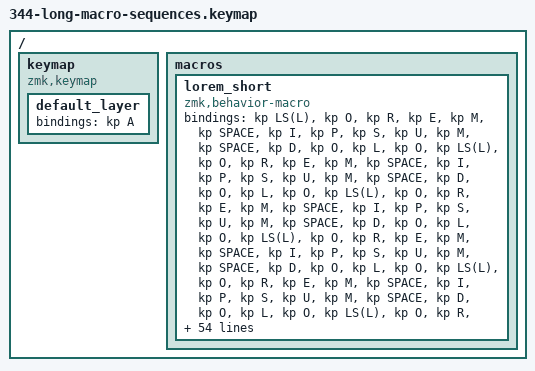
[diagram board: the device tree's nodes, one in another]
/* Issue #344: long macro payload regression; representative source from the issue comments. */
/{
    keymap {
        compatible = "zmk,keymap";
        default_layer { bindings = <&kp A>; };
    };
    macros {
        lorem_short: lorem_short {
            compatible = "zmk,behavior-macro";
            #binding-cells = <0>;
            bindings = <&kp LS(L) &kp O &kp R &kp E &kp M &kp SPACE &kp I &kp P &kp S &kp U &kp M &kp SPACE &kp D &kp O &kp L &kp O &kp LS(L) &kp O &kp R &kp E &kp M &kp SPACE &kp I &kp P &kp S &kp U &kp M &kp SPACE &kp D &kp O &kp L &kp O &kp LS(L) &kp O &kp R &kp E &kp M &kp SPACE &kp I &kp P &kp S &kp U &kp M &kp SPACE &kp D &kp O &kp L &kp O &kp LS(L) &kp O &kp R &kp E &kp M &kp SPACE &kp I &kp P &kp S &kp U &kp M &kp SPACE &kp D &kp O &kp L &kp O &kp LS(L) &kp O &kp R &kp E &kp M &kp SPACE &kp I &kp P &kp S &kp U &kp M &kp SPACE &kp D &kp O &kp L &kp O &kp LS(L) &kp O &kp R &kp E &kp M &kp SPACE &kp I &kp P &kp S &kp U &kp M &kp SPACE &kp D &kp O &kp L &kp O &kp LS(L) &kp O &kp R &kp E &kp M &kp SPACE &kp I &kp P &kp S &kp U &kp M &kp SPACE &kp D &kp O &kp L &kp O &kp LS(L) &kp O &kp R &kp E &kp M &kp SPACE &kp I &kp P &kp S &kp U &kp M &kp SPACE &kp D &kp O &kp L &kp O &kp LS(L) &kp O &kp R &kp E &kp M &kp SPACE &kp I &kp P &kp S &kp U &kp M &kp SPACE &kp D &kp O &kp L &kp O &kp LS(L) &kp O &kp R &kp E &kp M &kp SPACE &kp I &kp P &kp S &kp U &kp M &kp SPACE &kp D &kp O &kp L &kp O &kp LS(L) &kp O &kp R &kp E &kp M &kp SPACE &kp I &kp P &kp S &kp U &kp M &kp SPACE &kp D &kp O &kp L &kp O &kp LS(L) &kp O &kp R &kp E &kp M &kp SPACE &kp I &kp P &kp S &kp U &kp M &kp SPACE &kp D &kp O &kp L &kp O &kp LS(L) &kp O &kp R &kp E &kp M &kp SPACE &kp I &kp P &kp S &kp U &kp M &kp SPACE &kp D &kp O &kp L &kp O &kp LS(L) &kp O &kp R &kp E &kp M &kp SPACE &kp I &kp P &kp S &kp U &kp M &kp SPACE &kp D &kp O &kp L &kp O &kp LS(L) &kp O &kp R &kp E &kp M &kp SPACE &kp I &kp P &kp S &kp U &kp M &kp SPACE &kp D &kp O &kp L &kp O &kp LS(L) &kp O &kp R &kp E &kp M &kp SPACE &kp I &kp P &kp S &kp U &kp M &kp SPACE &kp D &kp O &kp L &kp O &kp LS(L) &kp O &kp R &kp E &kp M &kp SPACE &kp I &kp P &kp S &kp U &kp M &kp SPACE &kp D &kp O &kp L &kp O &kp LS(L) &kp O &kp R &kp E &kp M &kp SPACE &kp I &kp P &kp S &kp U &kp M &kp SPACE &kp D &kp O &kp L &kp O &kp LS(L) &kp O &kp R &kp E &kp M &kp SPACE &kp I &kp P &kp S &kp U &kp M &kp SPACE &kp D &kp O &kp L &kp O &kp LS(L) &kp O &kp R &kp E &kp M &kp SPACE &kp I &kp P &kp S &kp U &kp M &kp SPACE &kp D &kp O &kp L &kp O &kp LS(L) &kp O &kp R &kp E &kp M &kp SPACE &kp I &kp P &kp S &kp U &kp M &kp SPACE &kp D &kp O &kp L &kp O &kp LS(L) &kp O &kp R &kp E &kp M &kp SPACE &kp I &kp P &kp S &kp U &kp M &kp SPACE &kp D &kp O &kp L &kp O &kp LS(L) &kp O &kp R &kp E &kp M &kp SPACE &kp I &kp P &kp S &kp U &kp M &kp SPACE &kp D &kp O &kp L &kp O &kp LS(L) &kp O &kp R &kp E &kp M &kp SPACE &kp I &kp P &kp S &kp U &kp M &kp SPACE &kp D &kp O &kp L &kp O &kp LS(L) &kp O &kp R &kp E &kp M &kp SPACE &kp I &kp P &kp S &kp U &kp M &kp SPACE &kp D &kp O &kp L &kp O>;
            label = "LOREM_SHORT";
        };
    };
};
